# S6E2DF register map
File version: 1.1
CPU: CM4 r0p1, little endian, MPU, FPU, 4 interrupt priority bits
Registers are 32-bit, read-write, reset 0x0 unless marked. A register's access mark holds for its fields unless they carry their own. Offsets are from the block's base; [hi:lo] are bit positions; {n}, {i} and the like mark numbered series.

## LVD — Low-voltage Detection
Base 0x40035000
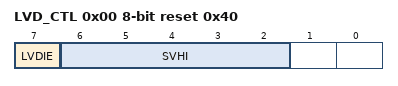
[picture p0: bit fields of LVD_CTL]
0x00 LVD_CTL 8-bit reset 0x40 — Low-voltage Detection Voltage Control Register
  [7] LVDIE — Low-voltage detection interrupt enable bit
  [6:2] SVHI — Low-voltage detection interrupt voltage setting bits
0x04 LVD_STR 8-bit ro — Low-voltage Detection Interrupt Factor Register
  [7] LVDIR — Low-voltage detection interrupt factor bit
0x08 LVD_CLR 8-bit reset 0x80 — Low-voltage Detection Interrupt Factor Clear Register
  [7] LVDCL — Low-voltage detection interrupt factor clear bit
0x0C LVD_RLR reset 0x1 — Low-voltage Detection Voltage Protection Register
  [31:0] LVDLCK — Low-voltage Detection Voltage Control Register protection bits
0x10 LVD_STR2 8-bit ro reset 0x40 — Low-voltage Detection Circuit Status Register
  [7] LVDIRDY — Low-voltage detection interrupt status flag

## DS — Low Power Consumption Mode
Base 0x40035100
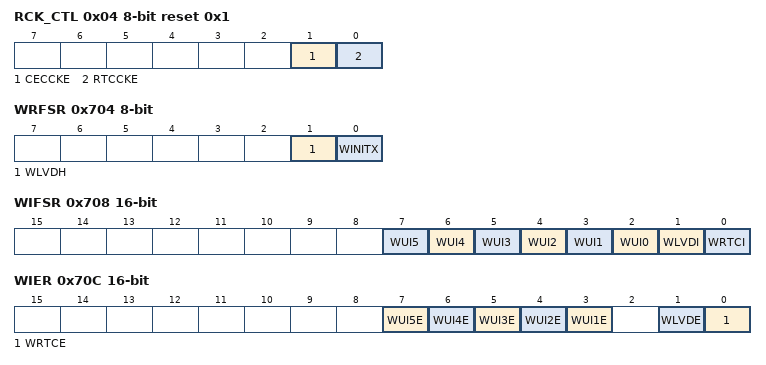
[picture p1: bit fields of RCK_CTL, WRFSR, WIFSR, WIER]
0x04 RCK_CTL 8-bit reset 0x1 — Sub Clock Control Register
  [1] CECCKE — CEC clock control bit
  [0] RTCCKE — RTC clock control bit
0x700 PMD_CTL 8-bit — RTC Mode Control Register
  [0] RTCE — RTC mode control bit
0x704 WRFSR 8-bit — Deep Standby Return Cause Register 1
  [1] WLVDH — Low-voltage detection reset return bit
  [0] WINITX — INITX pin input reset return bit
0x708 WIFSR 16-bit ro — Deep Standby Return Cause Register 2
  [n+2] WUI{n} (n=0..5) — WKUP pin input return bit {n}
  [1] WLVDI — LVD interrupt return bit
  [0] WRTCI — RTC interrupt return bit
0x70C WIER 16-bit — Deep Standby Return Enable Register
  [n+2] WUI{n}E (n=1..5) — WKUP pin input return enable bit {n}
  [1] WLVDE — LVD interrupt return enable bit
  [0] WRTCE — RTC interrupt return enable bit
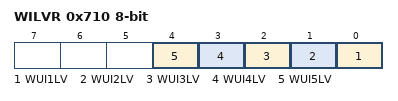
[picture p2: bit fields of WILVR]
0x710 WILVR 8-bit — WKUP Pin Input Level Register
  [n-1] WUI{n}LV (n=1..5) — WKUP pin input level select bit {n}
0x714 DSRAMR 8-bit — Deep Standby RAM Retention Register
  [1:0] SRAMR — On-chip SRAM retention control bits
{0x7FF+i} BUR{i:02} 8-bit (i=1..16) — Backup Registers from {i}

## USBCLK — USB/Ethernet Clock
Base 0x40036000
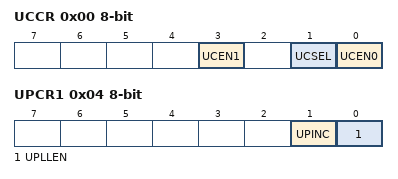
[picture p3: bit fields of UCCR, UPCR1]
0x00 UCCR 8-bit — USB Clock Control Register
  [3] UCEN1 — USB1 clock output enable bit
  [1] UCSEL — USB clock selection bit
  [0] UCEN0 — USB0 clock output enable bit
0x04 UPCR1 8-bit — USB-PLL Control Register 1
  [1] UPINC — USB-PLL input clock selection bit
  [0] UPLLEN — USB-PLL oscillation enable bit
0x08 UPCR2 8-bit — USB-PLL Control Register 2
  [2:0] UPOWT — USB-PLL oscillation stabilization wait time setting bit
0x0C UPCR3 8-bit — USB-PLL Control Register 3
  [4:0] UPLLK — Frequency division ratio (K) setting bit of the USB-PLL clock
0x10 UPCR4 8-bit reset 0x3B — USB-PLL Control Register 4
  [6:0] UPLLN — Frequency division ratio (N) setting bit of the USB-PLL clock
0x14 UP_STR 8-bit ro — USB-PLL Status Register
  [0] UPRDY — USB-PLL oscillation stabilization bit
0x18 UPINT_ENR 8-bit — USB-PLL Interrupt Factor Enable Register
  [0] UPCSE — USB-PLL oscillation stabilization wait complete interrupt enable bit
0x1C UPINT_CLR 8-bit wo — USB-PLL Interrupt Factor Clear Register
  [0] UPCSC — USB-PLL oscillation stabilization interrupt factor clear bit
0x20 UPINT_STR 8-bit ro — USB-PLL Interrupt Factor Status Register
  [0] UPCSI — USB-PLL interrupt factor status bit
0x24 UPCR5 8-bit reset 0x4 — USB-PLL Control Register 5
  [3:0] UPLLM — Frequency division ratio (M) setting bit of the USB-PLL clock
0x30 USBEN0 8-bit — USB0 Enable Register
  [0] USBEN0 — USB0 enable bit
0x34 USBEN1 8-bit — USB1 Enable Register
  [0] USBEN1 — USB1 enable bit

## CRC — CRC Registers
Base 0x40039000
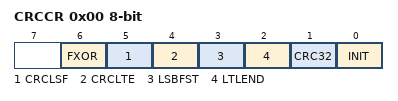
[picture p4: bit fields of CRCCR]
0x00 CRCCR 8-bit — CRC Control Register
  [6] FXOR — Initialization bit
  [5] CRCLSF — Final XOR control bit
  [4] CRCLTE — CRC result bit-order setting bit
  [3] LSBFST — CRC result byte-order setting bit
  [2] LTLEND — Bit-order setting bit
  [1] CRC32 — Byte-order setting bit
  [0] INIT — CRC mode selection bit
0x04 CRCINIT reset 0xFFFFFFFF — Initial Value Register
  [31:0] D — Initial value
0x08 CRCIN — Input Data Register
  [31:0] D — Input data
0x0C CRCR ro reset 0xFFFFFFFF — CRC Register
  [31:0] D — CRC Data
